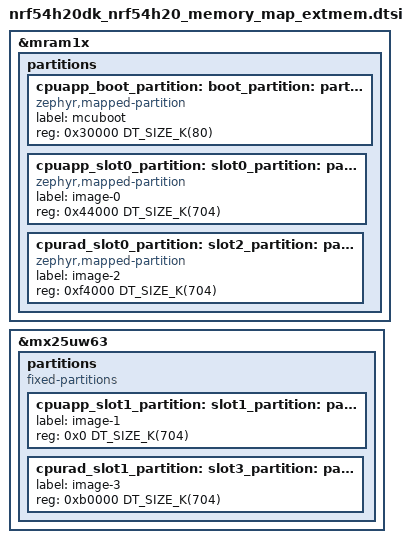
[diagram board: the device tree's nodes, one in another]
/*
 * Copyright (c) 2026 Nordic Semiconductor ASA
 *
 * SPDX-License-Identifier: LicenseRef-Nordic-5-Clause
 */

/delete-node/ &cpuapp_boot_partition;
/delete-node/ &cpuapp_slot0_partition;
/delete-node/ &cpurad_slot0_partition;
/delete-node/ &cpuapp_slot1_partition;
/delete-node/ &cpurad_slot1_partition;

&mram1x {
	partitions {
		cpuapp_boot_partition: boot_partition: partition@30000 {
			compatible = "zephyr,mapped-partition";
			label = "mcuboot";
			reg = <0x30000 DT_SIZE_K(80)>;
		};

		cpuapp_slot0_partition: slot0_partition: partition@44000 {
			compatible = "zephyr,mapped-partition";
			label = "image-0";
			reg = <0x44000 DT_SIZE_K(704)>;
		};

		cpurad_slot0_partition: slot2_partition: partition@f4000 {
			compatible = "zephyr,mapped-partition";
			label = "image-2";
			reg = <0xf4000 DT_SIZE_K(704)>;
		};
	};
};

&mx25uw63 {
	partitions {
		compatible = "fixed-partitions";
		#address-cells = <1>;
		#size-cells = <1>;

		cpuapp_slot1_partition: slot1_partition: partition@0 {
			label = "image-1";
			reg = <0x0 DT_SIZE_K(704)>;
		};

		cpurad_slot1_partition: slot3_partition: partition@b0000 {
			label = "image-3";
			reg = <0xb0000 DT_SIZE_K(704)>;
		};
	};
};
